# PIC32MX550F256H register map
Vendor: Microchip
Registers are 32-bit, read-write, reset 0x0 unless marked. A register's access mark holds for its fields unless they carry their own. Addresses are absolute, and some are shared; only a register's first bit layout is shown; [hi:lo] are bit positions; {n}, {i} and the like mark numbered series.

## ADC10
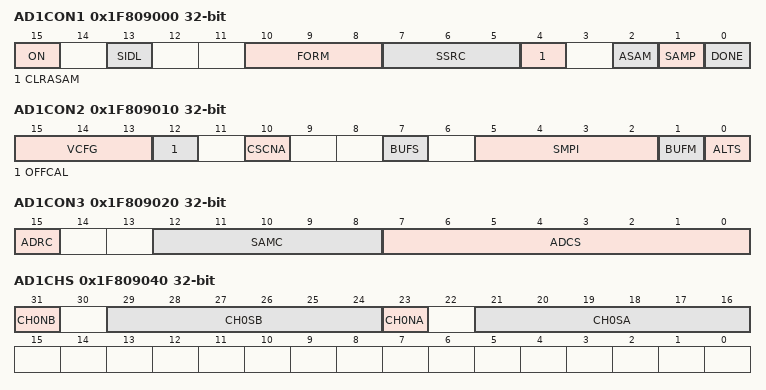
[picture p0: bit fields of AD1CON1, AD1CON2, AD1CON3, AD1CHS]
0x1F809000 AD1CON1
  [15] ON
  [13] SIDL
  [10:8] FORM
  [7:5] SSRC
  [4] CLRASAM
  [2] ASAM
  [1] SAMP
  [0] DONE — (can only be cleared)
0x1F809010 AD1CON2
  [15:13] VCFG, [12] OFFCAL, [10] CSCNA, [7] BUFS ro, [5:2] SMPI, [1] BUFM, [0] ALTS
0x1F809020 AD1CON3
  [15] ADRC, [12:8] SAMC, [7:0] ADCS
0x1F809040 AD1CHS reset not defined — (power-on value 0-xxxxxx0-xxxxxx----------------)
  [31] CH0NB, [29:24] CH0SB, [23] CH0NA, [21:16] CH0SA
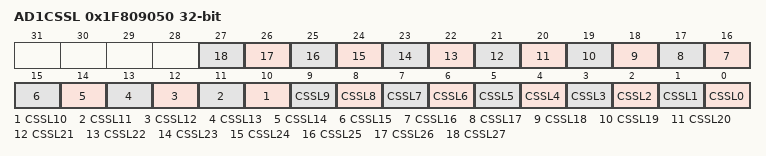
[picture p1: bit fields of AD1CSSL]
0x1F809050 AD1CSSL reset not defined — (power-on value ----xxxxxxxxxxxxxxxxxxxxxxxxxxxx)
  [n] CSSL{n} (n=0..27)
0x1F809060 AD1CSSL2 access not given reset not defined
{0x1F809070+0x10*i} ADC1BUF{i} ro (i=0..9)
0x1F809110 ADC1BUFA ro
0x1F809120 ADC1BUFB ro
0x1F809130 ADC1BUFC ro
0x1F809140 ADC1BUFD ro
0x1F809150 ADC1BUFE ro
0x1F809160 ADC1BUFF ro

## CVR
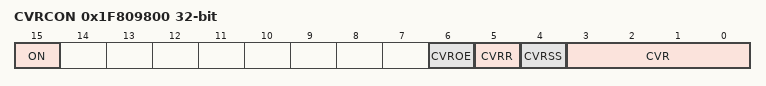
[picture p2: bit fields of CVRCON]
0x1F809800 CVRCON
  [15] ON, [6] CVROE, [5] CVRR, [4] CVRSS, [3:0] CVR

## CMP1
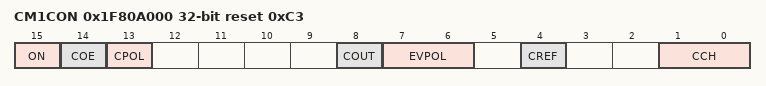
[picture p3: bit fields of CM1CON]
0x1F80A000 CM1CON reset 0xC3
  [15] ON, [14] COE, [13] CPOL, [8] COUT, [7:6] EVPOL, [4] CREF, [1:0] CCH

## CMP2
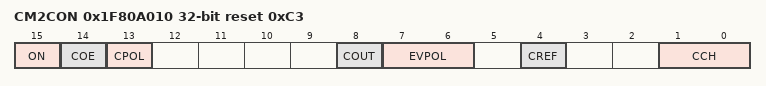
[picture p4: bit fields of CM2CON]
0x1F80A010 CM2CON reset 0xC3
  [15] ON, [14] COE, [13] CPOL, [8] COUT, [7:6] EVPOL, [4] CREF, [1:0] CCH

## CMP3
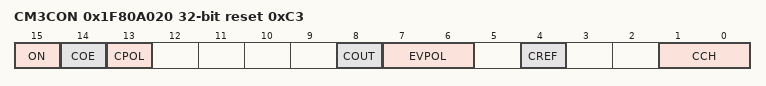
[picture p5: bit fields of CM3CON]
0x1F80A020 CM3CON reset 0xC3
  [15] ON, [14] COE, [13] CPOL, [8] COUT, [7:6] EVPOL, [4] CREF, [1:0] CCH

## cmp_control_pb
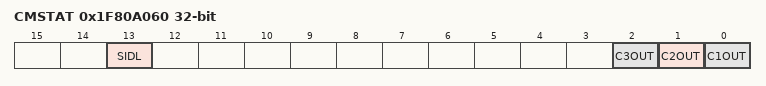
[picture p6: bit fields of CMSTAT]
0x1F80A060 CMSTAT reset not defined — (power-on value ------------------------00---x00)
  [13] SIDL, [2] C3OUT, [1] C2OUT ro, [0] C1OUT ro

## CTMU
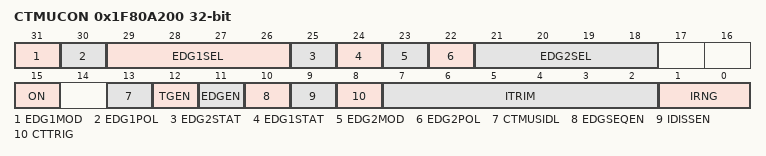
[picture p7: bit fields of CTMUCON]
0x1F80A200 CTMUCON
  [31] EDG1MOD, [30] EDG1POL, [29:26] EDG1SEL, [25] EDG2STAT, [24] EDG1STAT, [23] EDG2MOD, [22] EDG2POL, [21:18] EDG2SEL, [15] ON, [13] CTMUSIDL, [12] TGEN, [11] EDGEN, [10] EDGSEQEN, [9] IDISSEN, [8] CTTRIG, [7:2] ITRIM, [1:0] IRNG

## OSC
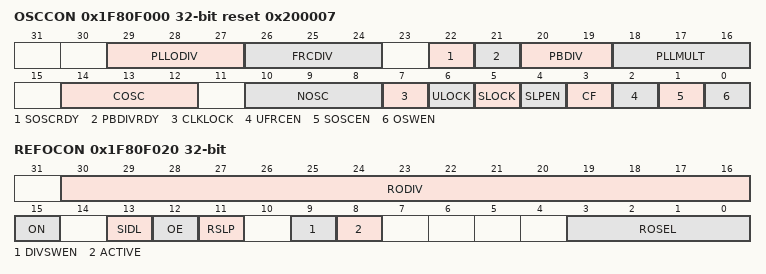
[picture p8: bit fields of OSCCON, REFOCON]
0x1F80F000 OSCCON reset 0x200007
  [29:27] PLLODIV, [26:24] FRCDIV, [22] SOSCRDY, [21] PBDIVRDY, [20:19] PBDIV, [18:16] PLLMULT, [14:12] COSC, [10:8] NOSC, [7] CLKLOCK, [6] ULOCK, [5] SLOCK, [4] SLPEN, [3] CF, [2] UFRCEN, [1] SOSCEN, [0] OSWEN
0x1F80F010 OSCTUN
  [5:0] TUN
0x1F80F020 REFOCON reset not defined — (power-on value -xxxxxxxxxxxxxxxxxxxxxxxx---xxxx)
  [30:16] RODIV, [15] ON, [13] SIDL, [12] OE, [11] RSLP, [9] DIVSWEN, [8] ACTIVE, [3:0] ROSEL
0x1F80F030 REFOTRIM reset not defined — (power-on value xxxxxxxxx-----------------------)
  [31:23] ROTRIM

## CFG
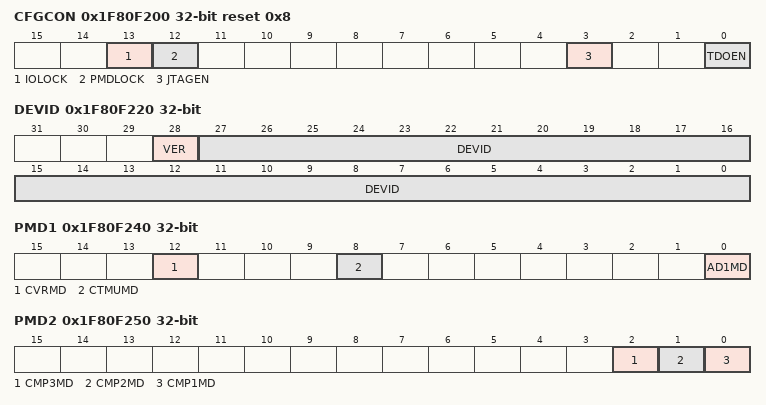
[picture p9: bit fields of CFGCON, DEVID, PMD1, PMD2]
0x1F80F200 CFGCON reset 0x8
  [13] IOLOCK, [12] PMDLOCK, [3] JTAGEN, [0] TDOEN
0x1F80F220 DEVID ro reset not defined — (power-on value xxxxxxxxxxxxxxxxxxxxxxxxxxxxxxxx)
  [28] VER, [27:0] DEVID
0x1F80F230 SYSKEY ro reset not defined — (power-on value xxxxxxxxxxxxxxxxxxxxxxxxxxxxxxxx)
0x1F80F240 PMD1
  [12] CVRMD, [8] CTMUMD, [0] AD1MD
0x1F80F250 PMD2
  [2] CMP3MD, [1] CMP2MD, [0] CMP1MD
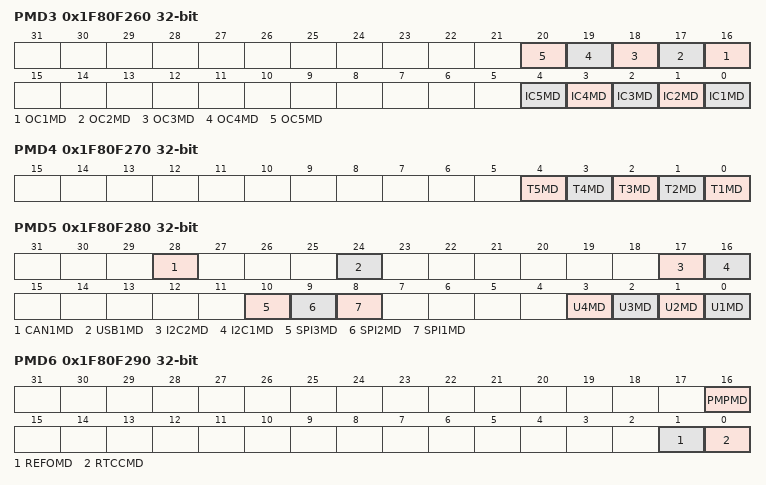
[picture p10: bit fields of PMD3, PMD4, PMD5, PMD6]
0x1F80F260 PMD3
  [n+15] OC{n}MD (n=1..5), [n-1] IC{n}MD (n=1..5)
0x1F80F270 PMD4
  [n-1] T{n}MD (n=1..5)
0x1F80F280 PMD5 reset not defined — (power-on value ---x---0------00-----x00----xx00)
  [28] CAN1MD, [24] USB1MD, [17] I2C2MD, [16] I2C1MD, [10] SPI3MD, [9] SPI2MD, [8] SPI1MD, [n-1] U{n}MD (n=1..4)
0x1F80F290 PMD6
  [16] PMPMD, [1] REFOMD, [0] RTCCMD

## NVM
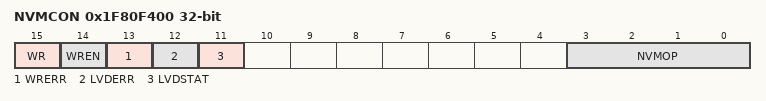
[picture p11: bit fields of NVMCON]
0x1F80F400 NVMCON
  [15] WR, [14] WREN, [13] WRERR, [12] LVDERR, [11] LVDSTAT, [3:0] NVMOP
0x1F80F410 NVMKEY wo
0x1F80F420 NVMADDR
0x1F80F430 NVMDATA
0x1F80F440 NVMSRCADDR

## RCON
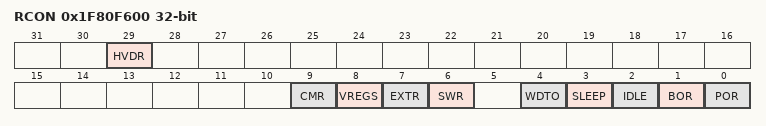
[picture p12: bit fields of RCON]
0x1F80F600 RCON reset not defined — (power-on value --x-------------------0000-00011)
  [29] HVDR, [9] CMR, [8] VREGS, [7] EXTR, [6] SWR, [4] WDTO, [3] SLEEP, [2] IDLE, [1] BOR, [0] POR
0x1F80F610 RSWRST
  [0] SWRST
